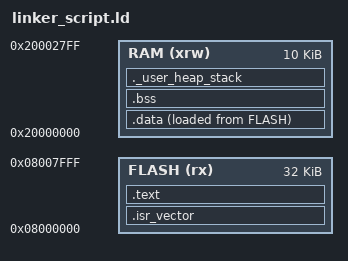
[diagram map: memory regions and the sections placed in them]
/*
******************************************************************************
**
** @file        : LinkerScript.ld
**
** @author      : Auto-generated by STM32CubeIDE
**
** @brief       : Linker script for STM32F103C6Tx Device from STM32F1 series
**                      32Kbytes FLASH
**                      10Kbytes RAM
**
**                Set heap size, stack size and stack location according
**                to application requirements.
**
**                Set memory bank area and size if external memory is used
**
**  Target      : STMicroelectronics STM32
**
**  Distribution: The file is distributed as is, without any warranty
**                of any kind.
**
******************************************************************************
** @attention
**
** Copyright (c) 2026 STMicroelectronics.
** All rights reserved.
**
** This software is licensed under terms that can be found in the LICENSE file
** in the root directory of this software component.
** If no LICENSE file comes with this software, it is provided AS-IS.
**
******************************************************************************
*/

/* Entry Point */
ENTRY(Reset_Handler)

/* Highest address of the user mode stack */
_estack = ORIGIN(RAM) + LENGTH(RAM); /* end of "RAM" Ram type memory */

//_Min_Heap_Size = 0x200; /* required amount of heap */
/*Если ты не используешь malloc и функции динамической памяти,куча не нужна.*/
    /* PROVIDE ( end = . ); */ 
_Min_Heap_Size = 0; /* required amount of heap */
_Min_Stack_Size = 0x400; /* required amount of stack */

/* Memories definition */
MEMORY
{
  RAM    (xrw)    : ORIGIN = 0x20000000,   LENGTH = 10K
  FLASH    (rx)    : ORIGIN = 0x8000000,   LENGTH = 32K
}

/* Sections */
SECTIONS
{
  .isr_vector : {
    . = ALIGN(4);
    KEEP(*(.isr_vector))
    . = ALIGN(4);
  } >FLASH

  .text : {
    . = ALIGN(4);
    *(.text)           /* Сначала основной код */
    *(.text*)          /* Потом остальные функции */
    *(.rodata)         /* Константы */
    *(.rodata*)
    
    . = ALIGN(4);
    _etext = .;
  } >FLASH

  _sidata = LOADADDR(.data);

  .data : {
    . = ALIGN(4);
    _sdata = .;
    *(.data)
    *(.data*)
    . = ALIGN(4);
    _edata = .;
  } >RAM AT> FLASH

   . = ALIGN(4);
  .bss : {
    _sbss = .;
    *(.bss)
    *(.bss*)
    *(COMMON)
    . = ALIGN(4);
    _ebss = .;
  } >RAM

    ._user_heap_stack :
  {
    . = ALIGN(8);
    /*Символы end и _end:
    Если ты не используешь malloc и функции динамической памяти, они тебе не нужны.*/
    /* PROVIDE ( end = . ); */ 
    /* PROVIDE ( _end = . ); */
    . = . + _Min_Heap_Size;
    . = . + _Min_Stack_Size;
    . = ALIGN(8);
  } >RAM

    /* Remove information from the compiler libraries */
  /DISCARD/ :
  {
    libc.a ( * )
    libm.a ( * )
    libgcc.a ( * )
  }
  /* Всё остальное — под нож, если не используешь специфику C++ */
}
